AUTOSAR XML (schema 4-0-3)
standard types defined: Boolean, UInt16, UInt32
package /AUTOSAR_Platform/DataConstrs
  range DC_Boolean: raw 0..1
  range DC_UInt16: raw 0..65535
package /PATAC/MSM/ComponentTypes
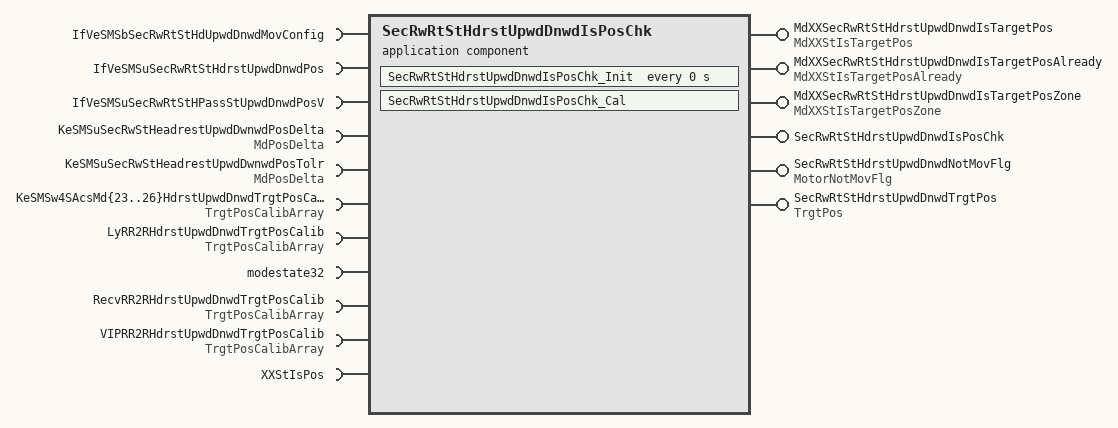
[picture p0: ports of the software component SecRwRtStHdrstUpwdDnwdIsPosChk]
  application sw component type SecRwRtStHdrstUpwdDnwdIsPosChk
    6 x provide port:
      MdXXSecRwRtStHdrstUpwdDnwdIsTargetPos: nonqueued-sender-com-spec=data-element=MdXXStIsTargetPos/Val, provided-interface=MdXXStIsTargetPos
      MdXXSecRwRtStHdrstUpwdDnwdIsTargetPosAlready: nonqueued-sender-com-spec=data-element=MdXXStIsTargetPosAlready/Val, provided-interface=MdXXStIsTargetPosAlready
      MdXXSecRwRtStHdrstUpwdDnwdIsTargetPosZone: nonqueued-sender-com-spec=data-element=MdXXStIsTargetPosZone/Val, provided-interface=MdXXStIsTargetPosZone
      SecRwRtStHdrstUpwdDnwdIsPosChk: server-com-spec{operation=Cal, queue-length=1}, provided-interface=SecRwRtStHdrstUpwdDnwdIsPosChk
      SecRwRtStHdrstUpwdDnwdNotMovFlg: nonqueued-sender-com-spec{data-element=MotorNotMovFlg/Val, init-value=0}, provided-interface=MotorNotMovFlg
      SecRwRtStHdrstUpwdDnwdTrgtPos: nonqueued-sender-com-spec{data-element=TrgtPos/Val, init-value=4095}, provided-interface=TrgtPos
    14 x require port:
      IfVeSMSbSecRwRtStHdUpwdDnwdMovConfig: nonqueued-receiver-com-spec{data-element=IfVeSMSbSecRwRtStHdUpwdDnwdMovConfig/Val, filter=data-filter-type=ALWAYS, init-value=0}, required-interface=IfVeSMSbSecRwRtStHdUpwdDnwdMovConfig
      IfVeSMSuSecRwRtStHdrstUpwdDnwdPos: nonqueued-receiver-com-spec{data-element=IfVeSMSuSecRwRtStHdrstUpwdDnwdPos/Val, filter=data-filter-type=ALWAYS, init-value=0}, required-interface=IfVeSMSuSecRwRtStHdrstUpwdDnwdPos
      IfVeSMSuSecRwRtStHPassStUpwdDnwdPosV: nonqueued-receiver-com-spec{data-element=IfVeSMSuSecRwRtStHPassStUpwdDnwdPosV/Val, filter=data-filter-type=ALWAYS, init-value=0}, required-interface=IfVeSMSuSecRwRtStHPassStUpwdDnwdPosV
      KeSMSuSecRwStHeadrestUpwdDwnwdPosDelta: parameter-require-com-spec{init-value=150, parameter=Val}, required-interface=MdPosDelta
      KeSMSuSecRwStHeadrestUpwdDwnwdPosTolr: parameter-require-com-spec{init-value=150, parameter=Val}, required-interface=MdPosDelta
      KeSMSw4SAcsMd{23..26}HdrstUpwdDnwdTrgtPosCalib: nonqueued-receiver-com-spec{data-element=TrgtPosArray, filter=data-filter-type=ALWAYS, init-value=[4095, 4095, 4095]}, required-interface=TrgtPosCalibArray
      LyRR2RHdrstUpwdDnwdTrgtPosCalib: nonqueued-receiver-com-spec{data-element=TrgtPosArray, filter=data-filter-type=ALWAYS, init-value=[4095, 4095, 4095]}, required-interface=TrgtPosCalibArray
      modestate32: nonqueued-receiver-com-spec{data-element=modestate32/Val, filter=data-filter-type=ALWAYS, init-value=0}, required-interface=modestate32
      RecvRR2RHdrstUpwdDnwdTrgtPosCalib: nonqueued-receiver-com-spec{data-element=TrgtPosArray, filter=data-filter-type=ALWAYS, init-value=[4095, 4095, 4095]}, required-interface=TrgtPosCalibArray
      VIPRR2RHdrstUpwdDnwdTrgtPosCalib: nonqueued-receiver-com-spec{data-element=TrgtPosArray, filter=data-filter-type=ALWAYS, init-value=[4095, 4095, 4095]}, required-interface=TrgtPosCalibArray
      XXStIsPos: client-com-spec=Get, required-interface=XXStIsPos
    behavior SecRwRtStHdrstUpwdDnwdIsPosChk_InternalBehavior
      operation invoked event OIT_SecRwRtStHdrstUpwdDnwdIsPosChk_Cal_SecRwRtStHdrstUpwdDnwdIsPosChk_Cal: start-on-event=SecRwRtStHdrstUpwdDnwdIsPosChk_Cal, operation=SecRwRtStHdrstUpwdDnwdIsPosChk.Cal
      timing event SecRwRtStHdrstUpwdDnwdIsPosChk_InitEvent: start-on-event=SecRwRtStHdrstUpwdDnwdIsPosChk_Init, period=0
      runnable SecRwRtStHdrstUpwdDnwdIsPosChk_Cal
        data-receive-point-by-arguments:
          11 x access:
            REC_IfVeSMSbSecRwRtStHdUpwdDnwdMovConfig_Val: accessed-variable=IfVeSMSbSecRwRtStHdUpwdDnwdMovConfig.Val
            REC_IfVeSMSuSecRwRtStHdrstUpwdDnwdPos_Val: accessed-variable=IfVeSMSuSecRwRtStHdrstUpwdDnwdPos.Val
            REC_IfVeSMSuSecRwRtStHPassStUpwdDnwdPosV_Val: accessed-variable=IfVeSMSuSecRwRtStHPassStUpwdDnwdPosV.Val
            REC_KeSMSw4SAcsMd{23..26}HdrstUpwdDnwdTrgtPosCalib_TrgtPosArray: accessed-variable=KeSMSw4SAcsMd{23..26}HdrstUpwdDnwdTrgtPosCalib.TrgtPosArray
            REC_LyRR2RHdrstUpwdDnwdTrgtPosCalib_TrgtPosArray: accessed-variable=LyRR2RHdrstUpwdDnwdTrgtPosCalib.TrgtPosArray
            REC_modestate32_Val: accessed-variable=modestate32.Val
            REC_RecvRR2RHdrstUpwdDnwdTrgtPosCalib_TrgtPosArray: accessed-variable=RecvRR2RHdrstUpwdDnwdTrgtPosCalib.TrgtPosArray
            REC_VIPRR2RHdrstUpwdDnwdTrgtPosCalib_TrgtPosArray: accessed-variable=VIPRR2RHdrstUpwdDnwdTrgtPosCalib.TrgtPosArray
        data-send-points:
          5 x access:
            SEND_MdXXSecRwRtStHdrstUpwdDnwdIsTargetPos_Val: accessed-variable=MdXXSecRwRtStHdrstUpwdDnwdIsTargetPos.Val
            SEND_MdXXSecRwRtStHdrstUpwdDnwdIsTargetPosAlready_Val: accessed-variable=MdXXSecRwRtStHdrstUpwdDnwdIsTargetPosAlready.Val
            SEND_MdXXSecRwRtStHdrstUpwdDnwdIsTargetPosZone_Val: accessed-variable=MdXXSecRwRtStHdrstUpwdDnwdIsTargetPosZone.Val
            SEND_SecRwRtStHdrstUpwdDnwdNotMovFlg_Val: accessed-variable=SecRwRtStHdrstUpwdDnwdNotMovFlg.Val
            SEND_SecRwRtStHdrstUpwdDnwdTrgtPos_Val: accessed-variable=SecRwRtStHdrstUpwdDnwdTrgtPos.Val
        parameter access PA_KeSMSuSecRwStHeadrestUpwdDwnwdPosDelta_Val: accessed-parameter=KeSMSuSecRwStHeadrestUpwdDwnwdPosDelta.Val
        parameter access PA_KeSMSuSecRwStHeadrestUpwdDwnwdPosTolr_Val: accessed-parameter=KeSMSuSecRwStHeadrestUpwdDwnwdPosTolr.Val
        sync call SC_XXStIsPos_Get: operation=XXStIsPos.Get, timeout=0
      runnable SecRwRtStHdrstUpwdDnwdIsPosChk_Init
        parameter access PA_KeSMSuSecRwStHeadrestUpwdDwnwdPosDelta_Val: accessed-parameter=KeSMSuSecRwStHeadrestUpwdDwnwdPosDelta.Val
        parameter access PA_KeSMSuSecRwStHeadrestUpwdDwnwdPosTolr_Val: accessed-parameter=KeSMSuSecRwStHeadrestUpwdDwnwdPosTolr.Val
  swc implementation SecRwRtStHdrstUpwdDnwdIsPosChk_Implementation: behavior=SecRwRtStHdrstUpwdDnwdIsPosChk_InternalBehavior
    code-descriptors:
      code Default: artifact-descriptors=autosar-engineering-object={short-label=Default, category=SWSRC}
package /PATAC/MSM/ModeAdjust/CalPortInterface
  parameter interface MdPosDelta
    parameter data prototype Val: sw-calibration-access=READ-WRITE, type=UInt16
package /PATAC/MSM/ModeAdjust/DataType
  impl type TrgtPosCalibArray: category=ARRAY, sw-calibration-access=READ-ONLY, type-emitter=RTE  # 0:pos 1:max 2:min
    element Element: array-size=3, array-size-semantics=FIXED-SIZE, implementation-data-type=UInt16, invalid-value=0
package /PATAC/MSM/ModeAdjust/Interfaces
  sender receiver interface IfVeSMSuSecRwRtStHPassStUpwdDnwdPosV: invalidation-policy{data-element=IfVeSMSuSecRwRtStHPassStUpwdDnwdPosV/Val, handle-invalid=DONT-INVALIDATE}
    data Val: type=Implementation/Boolean
package /PATAC/MSM/ModeAdjust/PortInterface
  client server interface SecRwRtStHdrstUpwdDnwdIsPosChk
    operation Cal
  client server interface XXStIsPos
    operation Get
      8 x arg, all with server-argument-impl-policy=USE-ARGUMENT-TYPE:
        PosV: type=DataTypes/Boolean, direction=IN
        Pos: type=UInt16, direction=IN
        CalibArray: type=TrgtPosCalibArray, direction=IN
        Delta: type=UInt16, direction=IN
        Tolr: type=UInt16, direction=IN
        IsPos: type=DataTypes/Boolean, direction=OUT
        IsPosZone: type=DataTypes/Boolean, direction=OUT
        IsPosAlready: type=DataTypes/Boolean, direction=OUT
  7 x sender receiver interface:
    IfVeSMSbSecRwRtStHdUpwdDnwdMovConfig: invalidation-policy{data-element=IfVeSMSbSecRwRtStHdUpwdDnwdMovConfig/Val, handle-invalid=DONT-INVALIDATE}
      data Val: type=Implementation/Boolean
    MdXXStIsTargetPos: invalidation-policy{data-element=MdXXStIsTargetPos/Val, handle-invalid=DONT-INVALIDATE}
      data Val: type=UInt32
    MdXXStIsTargetPosAlready: invalidation-policy{data-element=MdXXStIsTargetPosAlready/Val, handle-invalid=DONT-INVALIDATE}
      data Val: type=UInt32
    MdXXStIsTargetPosZone: invalidation-policy{data-element=MdXXStIsTargetPosZone/Val, handle-invalid=DONT-INVALIDATE}
      data Val: type=UInt32
    modestate32: invalidation-policy{data-element=modestate32/Val, handle-invalid=DONT-INVALIDATE}
      data Val: type=UInt32
    MotorNotMovFlg: invalidation-policy{data-element=MotorNotMovFlg/Val, handle-invalid=DONT-INVALIDATE}
      data Val: type=Implementation/Boolean
    TrgtPosCalibArray: invalidation-policy{data-element=TrgtPosArray, handle-invalid=DONT-INVALIDATE}
      data TrgtPosArray: type=TrgtPosCalibArray  # 0:Pos 1:Max 2:Min
package /PATAC/MSM/PortInterfaces
  sender receiver interface IfVeSMSuSecRwRtStHdrstUpwdDnwdPos: invalidation-policy{data-element=IfVeSMSuSecRwRtStHdrstUpwdDnwdPos/Val, handle-invalid=DONT-INVALIDATE}
    data Val: type=UInt16
  sender receiver interface TrgtPos: invalidation-policy{data-element=TrgtPos/Val, handle-invalid=DONT-INVALIDATE}
    data Val: type=UInt16
